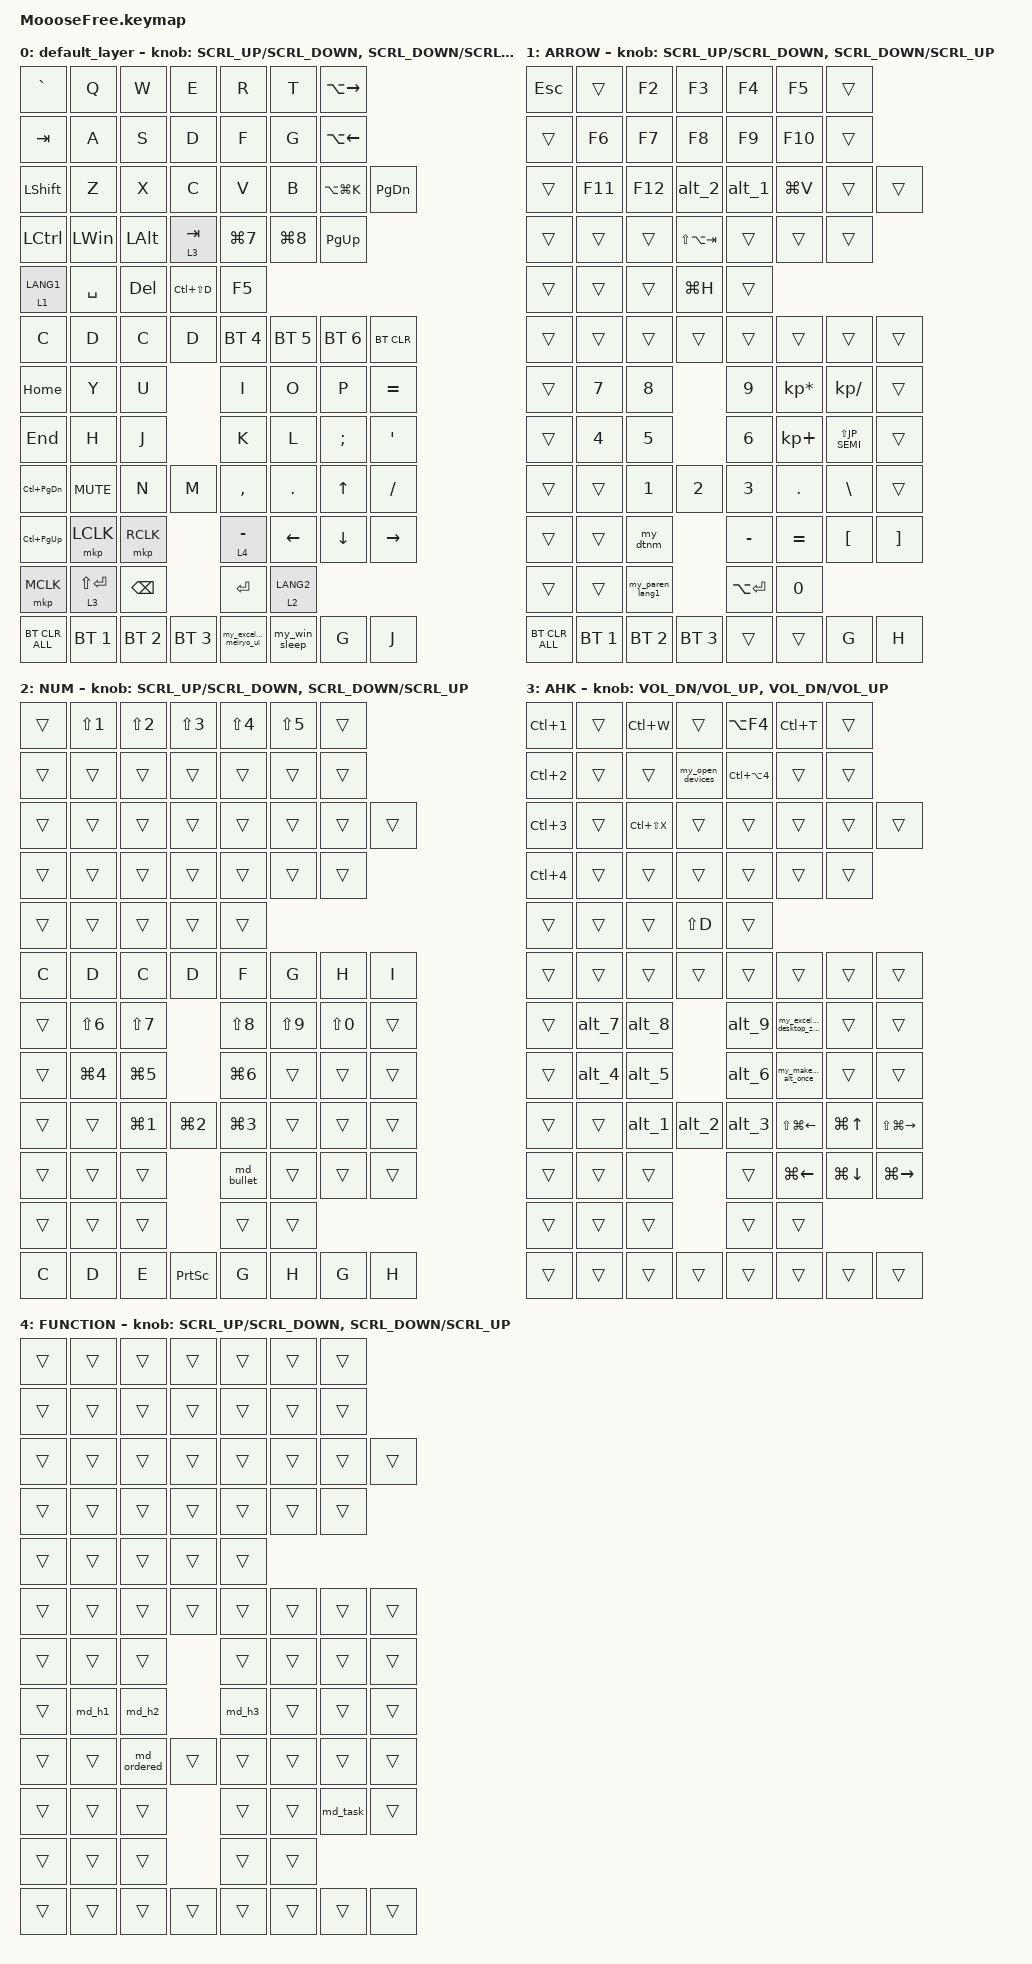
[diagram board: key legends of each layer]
#include <behaviors.dtsi>
#include <dt-bindings/zmk/bt.h>
#include <dt-bindings/zmk/keys.h>
#include <dt-bindings/zmk/mouse.h>
#include <dt-bindings/zmk/pointing.h>
#include <behaviors/rgbled_widget.dtsi>
#include <zephyr/dt-bindings/input/input-event-codes.h>

#define ZMK_POINTING_DEFAULT_SCRL_VAL 100

// Leyer
#define ARROW 1
#define NUM 2
#define AHK 3
#define FUNCTION 4

// Japanese
#define JP_MINUS MINUS        // -
#define JP_CARET EQUAL        // ^
#define JP_YEN   INT3         // ¥
#define JP_AT    LBKT         // @
#define JP_LBKT  RBKT         // [
#define JP_EISU  CAPS         // Eisu (英数)
#define JP_SEMI  SEMI         // ;
#define JP_COLON SQT          // :
#define JP_RBKT  NUHS         // ]
#define JP_COMMA COMMA        // ,
#define JP_DOT   DOT          // .
#define JP_SLASH SLASH        // /
#define JP_BSLH  INT1         // (backslash)
#define JP_MHEN  INT5         // Muhenkan (無変換)
#define JP_HENK  INT4         // Henkan (変換)
#define JP_EXCL  LS(N1)       // !
#define JP_DQT   LS(N2)       // "
#define JP_HASH  LS(N3)       // #
#define JP_DLLR  LS(N4)       // $
#define JP_PRCNT LS(N5)       // %
#define JP_AMPS  LS(N6)       // &
#define JP_SQT   LS(N7)       // '
#define JP_LPAR  LS(N8)       // (
#define JP_RPAR  LS(N9)       // )
#define JP_EQUAL LS(JP_MINUS) // =
#define JP_TILDE LS(JP_CARET) // ~
#define JP_PIPE  LS(JP_YEN)   // |
#define JP_GRAVE LS(JP_AT)    // `
#define JP_LBRC  LS(JP_LBKT)  // {
#define JP_CAPS  LS(JP_EISU)  // Caps Lock
#define JP_PLUS  LS(JP_SEMI)  // +
#define JP_ASTRK LS(JP_COLON) // *
#define JP_RBRC  LS(JP_RBKT)  // }
#define JP_LT    LS(JP_COMMA) // <
#define JP_RT    LS(JP_DOT)   // >
#define JP_QMARK LS(JP_SLASH) // ?
#define JP_UNDER LS(JP_BSLH)  // _

/ {
    macros {
        to_layer_0: to_layer_0 {
            compatible = "zmk,behavior-macro-one-param";
            #binding-cells = <1>;
            bindings = <&to 0 &macro_param_1to1 &kp MACRO_PLACEHOLDER>;
            label = "TO_LAYER_0";
        };
        md_bullet: md_bullet {
            compatible = "zmk,behavior-macro";
            label = "MD_BULLET";
            #binding-cells = <0>;
            wait-ms = <20>;
            tap-ms = <30>;
            bindings =
                <&macro_tap &kp LANG2>
              , <&macro_tap &kp MINUS>
              , <&macro_tap &kp SPACE>
              , <&macro_tap &kp LANG1>
              ;
        };
        my_dq: my_dq {
            #binding-cells = <0>;
            compatible = "zmk,behavior-macro";
            bindings = <&macro_tap &kp JP_MHEN>
                , <&macro_tap &kp LS(N2)>
                , <&macro_tap &kp LS(N2)>
                ;
        };
        my_sq: my_sq {
            #binding-cells = <0>;
            compatible = "zmk,behavior-macro";
            bindings = <&macro_tap &kp JP_MHEN>
                , <&macro_tap &kp LS(N7)>
                , <&macro_tap &kp LS(N7)>
                ;
        };

        my_kakko: my_kakko {
            compatible = "zmk,behavior-macro";
            #binding-cells = <0>;
            bindings = <&macro_tap &kp JP_MHEN>
                , <&macro_tap &kp LS(N8)>
                , <&macro_tap &kp LS(N9)>
                ;
        };
        my_open_devices: my_open_devices {
            compatible = "zmk,behavior-macro";
            label = "OPEN_DEVICES";
            #binding-cells = <0>;
            wait-ms = <40>;
            tap-ms = <40>;
            bindings =
                /* クイックリンクメニューを開き、200ms待ってRunを選ぶ */
                <&macro_wait_time 200>
              , <&macro_tap &kp LG(X)>
              , <&macro_wait_time 400>
              , <&macro_tap &kp R>

                /* Run表示を400ms待ち、通常の40ms間隔へ戻す */
              , <&macro_wait_time 40>
              , <&macro_tap &kp LANG2>

                /* Runの既存入力を選択して上書き */
              , <&macro_tap &kp LC(A)>

                /* Windows 設定 > デバイス > Bluetooth を直接開く */
              , <&macro_tap &kp M>
              , <&macro_tap &kp S>
              , <&macro_tap &kp MINUS>
              , <&macro_tap &kp S>
              , <&macro_tap &kp E>
              , <&macro_tap &kp T>
              , <&macro_tap &kp T>
              , <&macro_tap &kp I>
              , <&macro_tap &kp N>
              , <&macro_tap &kp G>
              , <&macro_tap &kp S>
              , <&macro_tap &kp COLON>
              , <&macro_tap &kp B>
              , <&macro_tap &kp L>
              , <&macro_tap &kp U>
              , <&macro_tap &kp E>
              , <&macro_tap &kp T>
              , <&macro_tap &kp O>
              , <&macro_tap &kp O>
              , <&macro_tap &kp T>
              , <&macro_tap &kp H>

                /* 実行後600ms待ち、日本語入力へ戻す */
              , <&macro_wait_time 600>
              , <&macro_tap &kp ENTER>
              , <&macro_wait_time 40>
              , <&macro_tap &kp LANG1>
              ;
        };
        my_make_link_alt_once: my_make_link_alt_once {
            compatible = "zmk,behavior-macro";
            #binding-cells = <0>;
            bindings =
                /* Alt 単押し */
                <&macro_tap &kp LALT>

                /* 続けて Z → S → C */
              , <&macro_tap &kp Z>
              , <&macro_tap &kp S>
              , <&macro_tap &kp C>
              ;
        };
        my_excel_open_desktop_zmo: my_excel_open_desktop_zmo {
            compatible = "zmk,behavior-macro";
            #binding-cells = <0>;
        
            bindings =
                /* KeyTips を出す */
                <&macro_tap &kp LALT>
              , <&macro_wait_time 300>
        
                /* Z → M → O */
              , <&macro_tap &kp Z>
              , <&macro_wait_time 300>
              , <&macro_tap &kp M>
              , <&macro_wait_time 300>
              , <&macro_tap &kp O>
              ;
        };
        my_win_sleep: my_win_sleep {
            compatible = "zmk,behavior-macro";
            #binding-cells = <0>;
        
            /* ここで “基本の待ち” を入れておくのも安定に効く */
            wait-ms = <20>;
            tap-ms = <30>;
        
            bindings =
                /* 余計なポップアップ/IME候補を閉じる（効くときは効く） */
                <&macro_tap     &kp ESC>
              , <&macro_tap     &kp ESC>
        
                /* 念のため Win 押しっぱ状態を解除 */
              , <&macro_release &kp LGUI>
        
                /* Win+X */
              , <&macro_press   &kp LGUI>
              , <&macro_tap     &kp X>
              , <&macro_release &kp LGUI>
        
                /* ★最重要：Win+Xメニューが開ききるまで待つ */
              , <&macro_wait_time 400>
        
                /* U（シャットダウンまたはサインアウト） */
              , <&macro_tap     &kp U>
        
                /* ★サブメニューが開くまで待つ */
              , <&macro_wait_time 400>
        
                /* S（スリープ） */
              , <&macro_tap     &kp S>
        
                /* 保険：最後にもう一回Win解除 */
              , <&macro_release &kp LGUI>
              ;
        };
        alt_1: alt_1 {
            compatible = "zmk,behavior-macro";
            label = "ALT_1";
            #binding-cells = <0>;
            bindings =
                <&macro_tap &kp LALT>
              , <&macro_tap &kp N1>
              ;
        };
    
        alt_2: alt_2 {
            compatible = "zmk,behavior-macro";
            label = "ALT_2";
            #binding-cells = <0>;
            bindings =
                <&macro_tap &kp LALT>
              , <&macro_tap &kp N2>
              ;
        };
    
        alt_3: alt_3 {
            compatible = "zmk,behavior-macro";
            label = "ALT_3";
            #binding-cells = <0>;
            bindings =
                <&macro_tap &kp LALT>
              , <&macro_tap &kp N3>
              ;
        };
    
        alt_4: alt_4 {
            compatible = "zmk,behavior-macro";
            label = "ALT_4";
            #binding-cells = <0>;
            bindings =
                <&macro_tap &kp LALT>
              , <&macro_tap &kp N4>
              ;
        };
    
        alt_5: alt_5 {
            compatible = "zmk,behavior-macro";
            label = "ALT_5";
            #binding-cells = <0>;
            bindings =
                <&macro_tap &kp LALT>
              , <&macro_tap &kp N5>
              ;
        };
    
        alt_6: alt_6 {
            compatible = "zmk,behavior-macro";
            label = "ALT_6";
            #binding-cells = <0>;
            bindings =
                <&macro_tap &kp LALT>
              , <&macro_tap &kp N6>
              ;
        };
    
        alt_7: alt_7 {
            compatible = "zmk,behavior-macro";
            label = "ALT_7";
            #binding-cells = <0>;
            bindings =
                <&macro_tap &kp LALT>
              , <&macro_tap &kp N7>
              ;
        };
    
        alt_8: alt_8 {
            compatible = "zmk,behavior-macro";
            label = "ALT_8";
            #binding-cells = <0>;
            bindings =
                <&macro_tap &kp LALT>
              , <&macro_tap &kp N8>
              ;
        };
    
        alt_9: alt_9 {
            compatible = "zmk,behavior-macro";
            label = "ALT_9";
            #binding-cells = <0>;
            bindings =
                <&macro_tap &kp LALT>
              , <&macro_tap &kp N9>
              ;
        };
        my_excel_font_meiryo_ui: my_excel_font_meiryo_ui {
            compatible = "zmk,behavior-macro";
            #binding-cells = <0>;
            bindings =
                /* 誤爆防止：英数側へ寄せる（環境により LANG1/LANG2 は入れ替え） */
                <&macro_tap &kp LANG2>
        
                /* 余計な選択状態を解除 */
              , <&macro_tap &kp ESC>
              , <&macro_tap &kp ESC>
        
                /* 全セル選択（2回でシート全体まで行きやすい） */
              , <&macro_press &kp LCTRL>
              , <&macro_tap   &kp A>
              , <&macro_release &kp LCTRL>
        
              , <&macro_press &kp LCTRL>
              , <&macro_tap   &kp A>
              , <&macro_release &kp LCTRL>
        
                /* KeyTips: Alt → H → F → F （ホーム→フォント名ボックス） */
              , <&macro_tap &kp LALT>
              , <&macro_tap &kp H>
              , <&macro_tap &kp F>
              , <&macro_tap &kp F>
        
                /* フォント名入力 */
              , <&macro_tap &kp M>
              , <&macro_tap &kp E>
              , <&macro_tap &kp I>
              , <&macro_tap &kp R>
              , <&macro_tap &kp Y>
              , <&macro_tap &kp O>
              , <&macro_tap &kp SPACE>
              , <&macro_tap &kp U>
              , <&macro_tap &kp I>
        
                /* 確定 */
              , <&macro_tap &kp ENTER>
        
                /* KeyTips終了（保険） */
              , <&macro_tap &kp ESC>
              ;
        };
        my_dtnm: my_dtnm {
            compatible = "zmk,behavior-macro";
            #binding-cells = <0>;
            bindings =
                /* 誤爆防止：Lang2 を1回 */
                <&macro_tap &kp LANG2>

                /* Ctrl + ; */
              , <&macro_press   &kp LCTRL>
              , <&macro_tap     &kp JP_SEMI>
              , <&macro_release &kp LCTRL>

                /* 半角スペース（日付と名前の間） */
              , <&macro_tap &kp SPACE>

                /* nm（実際の入力はAOYAMA） */
              , <&macro_tap &kp A>
              , <&macro_tap &kp O>
              , <&macro_tap &kp Y>
              , <&macro_tap &kp A>
              , <&macro_tap &kp M>
              , <&macro_tap &kp A>

                /* Alt + Enter */
              , <&macro_press   &kp LALT>
              , <&macro_tap     &kp ENTER>
              , <&macro_release &kp LALT>
              ;
        };
        my_paren_lang1: my_paren_lang1 {
            compatible = "zmk,behavior-macro";
            #binding-cells = <0>;
            bindings =
                /* 日本語入力側に寄せる（全角記号設定なら（ ）になる） */
                <&macro_tap &kp LANG1>
        
                /* 括弧（US配列位置：Shift+9 / Shift+0） */
              , <&macro_tap &kp LS(N9)>
              , <&macro_tap &kp LS(N0)>
        
                /* カーソルを括弧の中へ（セル編集モード前提） */
              , <&macro_tap &kp LEFT>
              ;
        };
        // Markdown helpers: force half-width input, type the prefix, then restore Japanese input.
        md_h1: md_h1 {
            compatible = "zmk,behavior-macro";
            #binding-cells = <0>;
            wait-ms = <20>;
            tap-ms = <30>;
            bindings =
                <&macro_tap &kp LANG2>
              , <&macro_tap &kp JP_HASH>
              , <&macro_tap &kp SPACE>
              , <&macro_tap &kp LANG1>
              ;
        };

        md_h2: md_h2 {
            compatible = "zmk,behavior-macro";
            #binding-cells = <0>;
            wait-ms = <20>;
            tap-ms = <30>;
            bindings =
                <&macro_tap &kp LANG2>
              , <&macro_tap &kp JP_HASH>
              , <&macro_tap &kp JP_HASH>
              , <&macro_tap &kp SPACE>
              , <&macro_tap &kp LANG1>
              ;
        };

        md_h3: md_h3 {
            compatible = "zmk,behavior-macro";
            #binding-cells = <0>;
            wait-ms = <20>;
            tap-ms = <30>;
            bindings =
                <&macro_tap &kp LANG2>
              , <&macro_tap &kp JP_HASH>
              , <&macro_tap &kp JP_HASH>
              , <&macro_tap &kp JP_HASH>
              , <&macro_tap &kp SPACE>
              , <&macro_tap &kp LANG1>
              ;
        };

        md_ordered: md_ordered {
            compatible = "zmk,behavior-macro";
            #binding-cells = <0>;
            wait-ms = <20>;
            tap-ms = <30>;
            bindings =
                <&macro_tap &kp LANG2>
              , <&macro_tap &kp N1>
              , <&macro_tap &kp JP_DOT>
              , <&macro_tap &kp SPACE>
              , <&macro_tap &kp LANG1>
              ;
        };

        md_task: md_task {
            compatible = "zmk,behavior-macro";
            #binding-cells = <0>;
            wait-ms = <20>;
            tap-ms = <30>;
            bindings =
                <&macro_tap &kp LANG2>
              , <&macro_tap &kp JP_MINUS>
              , <&macro_tap &kp SPACE>
              , <&macro_tap &kp JP_AT>
              , <&macro_tap &kp SPACE>
              , <&macro_tap &kp JP_LBKT>
              , <&macro_tap &kp SPACE>
              , <&macro_tap &kp LANG1>
              ;
        };

    };

    behaviors {
        lt_to_layer_0: lt_to_layer_0 {
            compatible = "zmk,behavior-hold-tap";
            label = "LAYER_TAP_TO_0";
            bindings = <&mo>, <&to_layer_0>;
            #binding-cells = <2>;
            tapping-term-ms = <200>;
        };
        rot_kp: sensor_rotate_kp {
            compatible = "zmk,behavior-sensor-rotate-var";
            #sensor-binding-cells = <2>;
            bindings = <&kp>, <&kp>;
            tap-ms = <20>;
        };
        rot_mkp: sensor_rotate_mkp {
            compatible = "zmk,behavior-sensor-rotate-var";
            #sensor-binding-cells = <2>;
            bindings = <&mkp>, <&mkp>;
            tap-ms = <20>;
        };
        mouse_scroll: mouse_wheel_scrl{
            compatible = "zmk,behavior-sensor-rotate-var";
            #sensor-binding-cells = <2>;
            bindings = <&msc>, <&msc>;
            tap-ms = <20>;
        };
        mouse_scroll2: mouse_wheel_scrl2{
            compatible = "zmk,behavior-sensor-rotate-var";
            #sensor-binding-cells = <2>;
            bindings = <&msc>, <&msc>;
            tap-ms = <16>;
        };
    };

    keymap {
        compatible = "zmk,keymap";
        default_layer {
            bindings = <
                &kp GRAVE     &kp Q      &kp W    &kp E   &kp R   &kp T                                       &kp LA(RIGHT)
                &kp TAB       &kp A      &kp S    &kp D   &kp F   &kp G                                       &kp LA(LEFT)
                &kp LSHIFT    &kp Z      &kp X    &kp C   &kp V   &kp B                                       &kp LA(LG(K))    &kp PG_DN
                &kp LCTRL     &kp LWIN   &kp LALT &lt_to_layer_0 3 TAB                &kp LG(N7)        &kp LG(N8)               &kp PG_UP
                &lt_to_layer_0 1 LANG1    &kp SPACE    &kp DEL    &kp LC(LS(D))    &kp F5
                &kp C   &kp D &kp C   &kp D     &bt BT_SEL 4  &bt BT_SEL 5   &bt BT_SEL 6                   &bt BT_CLR
        
                &kp HOME                              &kp Y       &kp U          &kp I          &kp O        &kp P         &kp EQUAL
                &kp END                            &kp H       &kp J          &kp K          &kp L        &kp JP_SEMI   &kp JP_COLON
                &kp LC(PG_DN)    &kp C_MUTE             &kp N       &kp M          &kp JP_COMMA   &kp JP_DOT   &kp UP        &kp JP_SLASH
                &kp LC(PG_UP)     &mkp LCLK        &mkp RCLK                        &lt_to_layer_0 4 MINUS     &kp LEFT      &kp DOWN      &kp RIGHT
                &mkp MCLK    &lt_to_layer_0 3 LS(ENTER)    &kp BSPC    &kp ENTER    &lt_to_layer_0 2 LANG2
                &bt BT_CLR_ALL             &bt BT_SEL 1    &bt BT_SEL 2   &bt BT_SEL 3         &my_excel_font_meiryo_ui  &my_win_sleep  &kp G   &kp J
            >;
            sensor-bindings = <&mouse_scroll2 SCRL_UP SCRL_DOWN>, <&mouse_scroll SCRL_DOWN SCRL_UP>;
        };
        ARROW {
            bindings = <
                &kp ESC       &trans     &kp F2      &kp F3      &kp F4      &kp F5                                      &trans
                &trans        &kp F6     &kp F7      &kp F8      &kp F9      &kp F10                                     &trans
                &trans        &kp F11    &kp F12     &alt_2   &alt_1       &kp LG(V)                   &trans    &trans
                &trans        &trans     &trans      &kp LS(LA(TAB))                 &trans      &trans    &trans
                                                     &trans      &trans      &trans       &kp LG(H)      &trans
                &trans        &trans     &trans      &trans       &trans      &trans      &trans                             &trans
        
                &trans                            &kp N7      &kp N8        &kp N9    &kp KP_ASTERISK  &kp KP_SLASH      &trans
                &trans                            &kp N4      &kp N5        &kp N6    &kp KP_PLUS      &kp LS(JP_SEMI)   &trans
                &trans       &trans             &kp N1      &kp N2        &kp N3    &kp JP_DOT       &kp BSLH          &trans
                &trans       &trans     &my_dtnm                                 &kp MINUS    &kp EQUAL    &kp JP_AT  &kp JP_LBKT
                &trans  &trans  &my_paren_lang1  &kp LA(ENTER)     &kp N0
                &bt BT_CLR_ALL             &bt BT_SEL 1    &bt BT_SEL 2   &bt BT_SEL 3         &trans  &trans  &kp G   &kp H
            >;
            sensor-bindings = <&mouse_scroll2 SCRL_UP SCRL_DOWN>, <&mouse_scroll SCRL_DOWN SCRL_UP>;
        };
        NUM {
            bindings = <
                &trans     &kp LS(N1)   &kp LS(N2)   &kp LS(N3)   &kp LS(N4)   &kp LS(N5)                            &trans
                &trans     &trans       &trans       &trans       &trans       &trans                                &trans
                &trans     &trans       &trans       &trans       &trans       &trans                                &trans    &trans
                &trans     &trans       &trans       &trans                           &trans               &trans     &trans
                                              &trans     &trans     &trans       &trans     &trans
                &kp C   &kp D   &kp C   &kp D        &kp F        &kp G          &kp H                               &kp I
        
                &trans                       &kp LS(N6)       &kp LS(N7)       &kp LS(N8)       &kp LS(N9)       &kp LS(N0)       &trans
                &trans                       &kp LG(N4)   &kp LG(N5)   &kp LG(N6)   &trans       &trans       &trans
                &trans    &trans    &kp LG(N1)   &kp LG(N2)   &kp LG(N3)   &trans    &trans       &trans
                &trans    &trans    &trans                                 &md_bullet    &trans    &trans    &trans
                &trans    &trans    &trans  &trans     &trans
                &kp C           &kp D   &kp E   &kp PSCRN           &kp G   &kp H &kp G   &kp H
            >;
            sensor-bindings = <&mouse_scroll2 SCRL_UP SCRL_DOWN>, <&mouse_scroll SCRL_DOWN SCRL_UP>;
        };
        AHK {
            bindings = <
                &kp LC(N1) &trans &kp LC(W) &trans &kp LA(F4) &kp LC(T) &trans
                &kp LC(N2) &trans &trans &my_open_devices &kp LC(LA(N4)) &trans &trans
                &kp LC(N3) &trans &kp LC(LS(X)) &trans &trans &trans &trans &trans
                &kp LC(N4) &trans &trans &trans &trans &trans &trans &trans
                &trans &trans &kp LS(D) &trans &trans
                &trans &trans &trans &trans &trans &trans &trans &trans
        
                &alt_7 &alt_8 &alt_9 &my_excel_open_desktop_zmo &trans &trans &trans
                &alt_4 &alt_5 &alt_6 &my_make_link_alt_once &trans &trans &trans &trans 
                &alt_1 &alt_2 &alt_3 &kp LS(LG(LEFT))    &kp LG(UP)    &kp LS(LG(RIGHT))
                &trans &trans &trans &trans &kp LG(LEFT)    &kp LG(DOWN)    &kp LG(RIGHT)
                &trans &trans &trans &trans &trans &trans &trans
                &trans &trans &trans &trans &trans &trans
            >;
            sensor-bindings = <&rot_kp C_VOL_DN C_VOL_UP &rot_kp C_VOL_DN C_VOL_UP>;
        };
        FUNCTION {
            bindings = <
                &trans  &trans  &trans  &trans  &trans  &trans  &trans
                &trans  &trans  &trans  &trans  &trans  &trans  &trans
                &trans  &trans  &trans  &trans  &trans  &trans  &trans  &trans
                &trans  &trans  &trans  &trans  &trans  &trans  &trans
                &trans  &trans  &trans  &trans  &trans
                &trans  &trans  &trans  &trans  &trans  &trans  &trans  &trans

                &trans  &trans  &trans       &trans       &trans  &trans  &trans
                &trans  &md_h1  &md_h2       &md_h3       &trans  &trans  &trans
                &trans  &trans  &md_ordered  &trans       &trans  &trans  &trans  &trans
                &trans  &trans  &trans       &trans       &trans  &md_task  &trans
                &trans  &trans  &trans       &trans       &trans
                &trans  &trans  &trans       &trans       &trans  &trans  &trans  &trans
            >;
            sensor-bindings = <&mouse_scroll2 SCRL_UP SCRL_DOWN>, <&mouse_scroll SCRL_DOWN SCRL_UP>;
        };
    };
};
